# K1921VG5T register map
Vendor: NIIET; Series: K1921VKx; File version: 1.1
CPU: CM4 r0p1, Endian.LITTLE endian, MPU, FPU
Registers are 32-bit, read-write, reset 0x0 unless marked. A register's access mark holds for its fields unless they carry their own. Offsets are from the block's base; [hi:lo] are bit positions; {n}, {i} and the like mark numbered series.

## SIU — System integration unit
Base 0x50003000
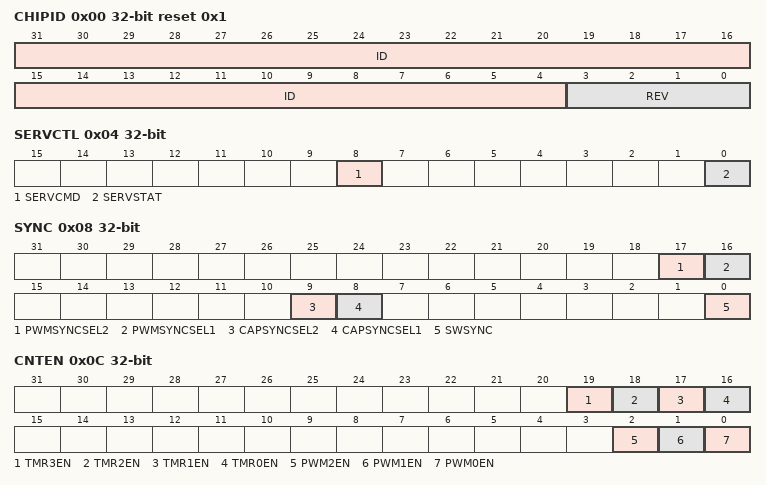
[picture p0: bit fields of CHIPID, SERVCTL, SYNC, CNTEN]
0x00 CHIPID ro reset 0x1 — Chip identifier
  [31:4] ID — Model ID
  [3:0] REV — Revision number
0x04 SERVCTL — Service mode Register
  [8] SERVCMD — Service mode erase comand/status
  [0] SERVSTAT ro — Service mode status
0x08 SYNC — Sync PWM/CAP register
  [17] PWMSYNCSEL2 — PWM sync scheme control
  [16] PWMSYNCSEL1 — PWM sync scheme control
  [9] CAPSYNCSEL2 — CAP sync scheme control
  [8] CAPSYNCSEL1 — CAP sync scheme control
  [0] SWSYNC — SYNCI pulse software emulation on PWM0
0x0C CNTEN — PWM/TMR count enable register enable register
  [19] TMR3EN — Enable count for timer 3
  [18] TMR2EN — Enable count for timer 2
  [17] TMR1EN — Enable count for TMR 1
  [16] TMR0EN — Enable count for TMR 0
  [2] PWM2EN — Enable count for PWM 2
  [1] PWM1EN — Enable count for PWM 1
  [0] PWM0EN — Enable count for PWM 0
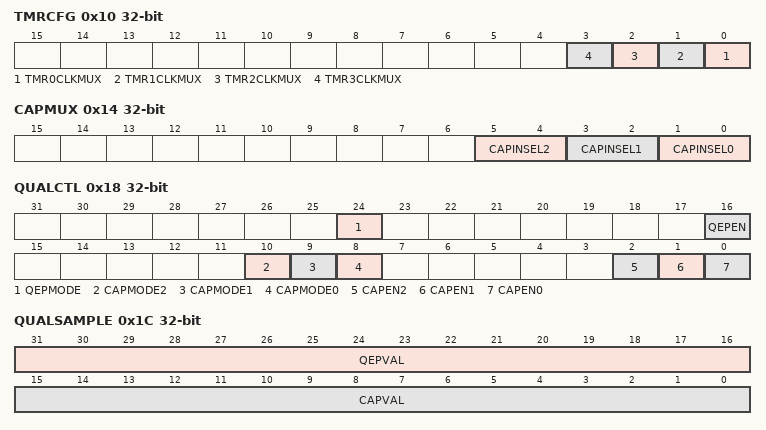
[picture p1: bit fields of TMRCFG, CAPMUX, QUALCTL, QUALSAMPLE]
0x10 TMRCFG — TMR external clock config
  [all] fields
    0=EXTPIN (external controler pin); 1=PRETIMER (previous timer PWM-output)
  [n] TMR{n}CLKMUX (n=0..3) — Select ecternal clock source
0x14 CAPMUX — CAP input mux control register
  [5:4] CAPINSEL2 — Select input source for CAP2
    0=CAP2 (default CAP2 input); 1=QEPA (QEP A input); 2=QEPB (QEP B input); 3=QEPI (QEP I input)
  [3:2] CAPINSEL1 — Select input source for CAP1
    0=CAP1 (default CAP1 input); 1=QEPA (QEP A input); 2=QEPB (QEP B input); 3=QEPI (QEP I input)
  [1:0] CAPINSEL0 — Select input source for CAP0
    0=CAP0 (default CAP0 input); 1=QEPA (QEP A input); 2=QEPB (QEP B input); 3=QEPI (QEP I input)
0x18 QUALCTL — QEP and ECAP qualifier control register
  [24] QEPMODE — Select mode of qualifier for QEP0
  [16] QEPEN — Enable qualifier for QEP0
  [10] CAPMODE2 — Select mode of qualifier for CAP2
  [9] CAPMODE1 — Select mode of qualifier for CAP1
  [8] CAPMODE0 — Select mode of qualifier for CAP0
  [2] CAPEN2 — Enable qualifier for CAP2
  [1] CAPEN1 — Enable qualifier for CAP1
  [0] CAPEN0 — Enable qualifier for CAP0
0x1C QUALSAMPLE — QEP and CAP qualifier sample period set register
  [31:16] QEPVAL — Set sample period of qualifer for all QEPs
  [15:0] CAPVAL — Set sample period of qualifer for all CAPs
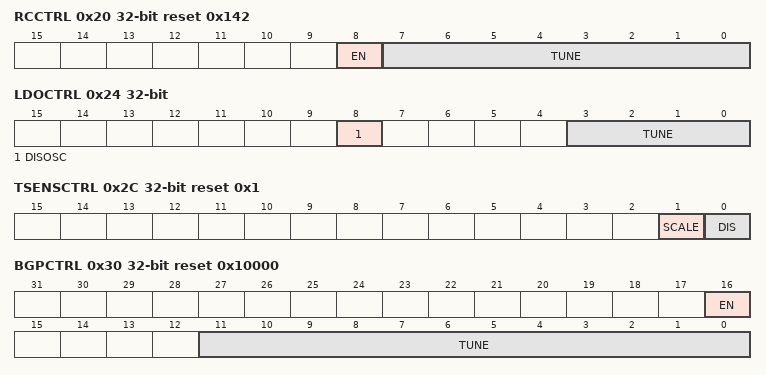
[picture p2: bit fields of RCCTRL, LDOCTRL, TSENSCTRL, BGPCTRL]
0x20 RCCTRL reset 0x142 — RC generator control register
  [8] EN — Internal oscillator enable
  [7:0] TUNE — Tune RC generator period
0x24 LDOCTRL — LDO control register
  [8] DISOSC — Disable 100kHz oscillator
    0=ENABLEOSC (Enable 100kHz oscillator); 1=DISABLEOSC (Disable 100kHz oscillator)
  [3:0] TUNE — Tune LDO output voltage
0x28 CPESTAT ro — CPE status register
  [0] CPE — CPE status
0x2C TSENSCTRL reset 0x1 — T-sensor control register
  [1] SCALE — Sensor type
  [0] DIS — Disable tsensor
0x30 BGPCTRL reset 0x10000 — Bandgap control register
  [16] EN — Internal oscillator enable
  [11:0] TUNE — Tune bandgap voltage
0x34 BOOTSELSTAT ro — BOOTSEL status register
  [0] BOOTSEL — BOOTSEL status
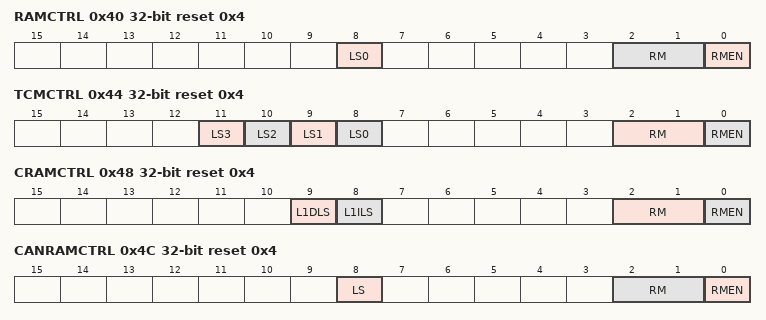
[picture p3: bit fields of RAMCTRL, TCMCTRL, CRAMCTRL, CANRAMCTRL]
0x40 RAMCTRL reset 0x4 — SRAM control register
  [8] LS0 — Ligth Sleep RAM part 0 (0..16k)
  [2:1] RM — Read-Write Margin value
  [0] RMEN — Enable to use Read-Write Margin
0x44 TCMCTRL reset 0x4 — Core Tightly-Coupled Memory SRAM control
  [11] LS3 — Ligth Sleep TCM RAM part 3 (24k..32k)
  [10] LS2 — Ligth Sleep TCM RAM part 2 (16..24k)
  [9] LS1 — Ligth Sleep TCM RAM part 1 (8k..16k)
  [8] LS0 — Ligth Sleep TCM RAM part 0 (0..8k)
  [2:1] RM — Read-Write Margin value
  [0] RMEN — Enable to use Read-Write Margin
0x48 CRAMCTRL reset 0x4 — Core Cache SRAM control
  [9] L1DLS — Ligth Sleep L1 Data cache RAM
  [8] L1ILS — Ligth Sleep L1 Instruction cache RAM
  [2:1] RM — Read-Write Margin value
  [0] RMEN — Enable to use Read-Write Margin
0x4C CANRAMCTRL reset 0x4 — CAN SRAM control
  [8] LS — Ligth Sleep CAN RAM
  [2:1] RM — Read-Write Margin value
  [0] RMEN — Enable to use Read-Write Margin
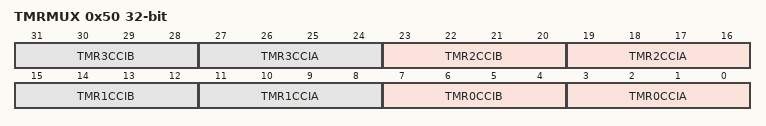
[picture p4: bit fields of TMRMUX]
0x50 TMRMUX — TMR ccix input select
  [all] fields
    {v}=TMR{v} (External pin TMR{v}) (v=0..3); 4=GPIOA (GPIOA adc soc impulse); 5=GPIOB (GPIOB adc soc impulse); 6=PWM0A (PWM0 adc soc chanel A impulse); 7=PWM0B (PWM0 adc soc chanel B impulse); 8=PWM1A (PWM1 adc soc chanel A impulse); 9=PWM1B (PWM1 adc soc chanel B impulse); 10=PWM2A (PWM2 adc soc chanel A impulse); 11=PWM2B (PWM2 adc soc chanel B impulse)
  [8n+7:8n+4] TMR{n}CCIB (n=0..3) — Select signal for TMR{n} CCIB input
  [8n+3:8n] TMR{n}CCIA (n=0..3) — Select signal for TMR{n} CCIA input
